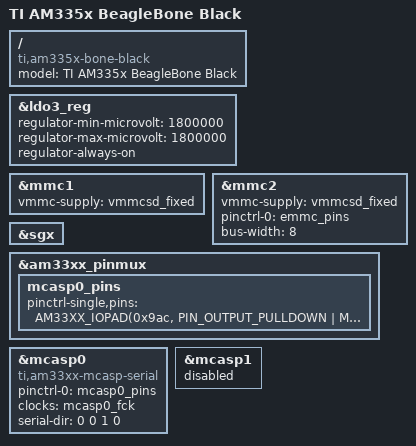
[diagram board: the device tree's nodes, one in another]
/*
 * Copyright (C) 2012 Texas Instruments Incorporated - http://www.ti.com/
 *
 * This program is free software; you can redistribute it and/or modify
 * it under the terms of the GNU General Public License version 2 as
 * published by the Free Software Foundation.
 */
/dts-v1/;

#include "am33xx.dtsi"
#include "am33xx-es2.dtsi"
#include "am335x-bone-common.dtsi"
#include "am33xx-overlay-edma-fix.dtsi"
#include <dt-bindings/display/tda998x.h>
/* #include "am335x-bone-jtag.dtsi" */

/ {
	model = "TI AM335x BeagleBone Black";
	compatible = "ti,am335x-bone-black", "ti,am335x-bone", "ti,am33xx";
};

&ldo3_reg {
	regulator-min-microvolt = <1800000>;
	regulator-max-microvolt = <1800000>;
	regulator-always-on;
};

&mmc1 {
	vmmc-supply = <&vmmcsd_fixed>;
};

&mmc2 {
	vmmc-supply = <&vmmcsd_fixed>;
	pinctrl-names = "default";
	pinctrl-0 = <&emmc_pins>;
	bus-width = <8>;
	status = "okay";
};

&sgx {
	status = "okay";
};

&am33xx_pinmux {
	mcasp0_pins: mcasp0_pins {
		pinctrl-single,pins = <
			AM33XX_IOPAD(0x9ac, PIN_OUTPUT_PULLDOWN | MUX_MODE0) /* mcasp0_ahcklx.mcasp0_ahclkx P9_25 */
			AM33XX_IOPAD(0x99c, PIN_OUTPUT_PULLDOWN | MUX_MODE0) /* mcasp0_ahclkr.mcasp0_ahclkr P9_28 */
			AM33XX_IOPAD(0x994, PIN_OUTPUT_PULLDOWN | MUX_MODE0) /* mcasp0_fsx.mcasp0_fsx P9_29 */
			AM33XX_IOPAD(0x990, PIN_OUTPUT_PULLDOWN | MUX_MODE0) /* mcasp0_aclkx.mcasp0_aclkx P9_31 */
			AM33XX_IOPAD(0x998, PIN_OUTPUT_PULLDOWN | MUX_MODE0) /* mcasp0_axr0.mcasp0_axr0 P9_30 */
			AM33XX_IOPAD(0x8d8, PIN_INPUT_PULLDOWN | MUX_MODE3) /* mcasp0_axr1.mcasp0_axr1 P8_31 */
			AM33XX_IOPAD(0x8d0, PIN_OUTPUT_PULLDOWN | MUX_MODE3) /* mcasp0_aclkr.mcasp0_aclkr P8_35 */
			AM33XX_IOPAD(0x8d4, PIN_OUTPUT_PULLDOWN | MUX_MODE3) /* mcasp0_fsr.mcasp0_fsr P8_33 */
			AM33XX_IOPAD(0x86c, PIN_OUTPUT_PULLDOWN | MUX_MODE7) /* gpmc_a11.GPIO1_27 */
		>;
	};
};

&mcasp0	{
	compatible = "ti,am33xx-mcasp-serial";
	pinctrl-names = "default";
	pinctrl-0 = <&mcasp0_pins>;
	status = "okay";
	clocks = <&mcasp0_fck>;
	serial-dir = <	/* 0: INACTIVE, 1: TX, 2: RX */
			0 0 1 0
		>;
};

&mcasp1 {
	status = "disabled";
};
